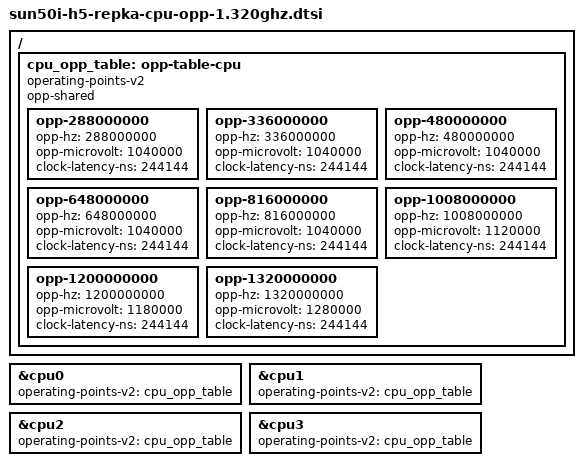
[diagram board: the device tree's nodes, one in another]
// SPDX-License-Identifier: (GPL-2.0+ OR MIT)
// Copyright (C) 2020 Chen-Yu Tsai <wens@csie.org>

/ {
	cpu_opp_table: opp-table-cpu {
		compatible = "operating-points-v2";
		opp-shared;

		opp-288000000 {
			opp-hz = /bits/ 64 <288000000>;
			opp-microvolt = <1040000>;
			clock-latency-ns = <244144>; /* 8 32k periods */
		};

		opp-336000000 {
			opp-hz = /bits/ 64 <336000000>;
			opp-microvolt = <1040000>;
			clock-latency-ns = <244144>; /* 8 32k periods */
		};

		opp-480000000 {
			opp-hz = /bits/ 64 <480000000>;
			opp-microvolt = <1040000>;
			clock-latency-ns = <244144>; /* 8 32k periods */
		};

		opp-648000000 {
			opp-hz = /bits/ 64 <648000000>;
			opp-microvolt = <1040000>;
			clock-latency-ns = <244144>; /* 8 32k periods */
		};

		opp-816000000 {
			opp-hz = /bits/ 64 <816000000>;
			opp-microvolt = <1040000>;
			clock-latency-ns = <244144>; /* 8 32k periods */
		};

		opp-1008000000 {
			opp-hz = /bits/ 64 <1008000000>;
			opp-microvolt = <1120000>;
			clock-latency-ns = <244144>; /* 8 32k periods */
		}; 

		opp-1200000000 {
			opp-hz = /bits/ 64 <1200000000>;
			opp-microvolt = <1180000>;
			clock-latency-ns = <244144>; /* 8 32k periods */
		};

		opp-1320000000 {
			opp-hz = /bits/ 64 <1320000000>;
			opp-microvolt = <1280000>;
			clock-latency-ns = <244144>; /* 8 32k periods  */
		};
	};
};

&cpu0 {
	operating-points-v2 = <&cpu_opp_table>;
};

&cpu1 {
	operating-points-v2 = <&cpu_opp_table>;
};

&cpu2 {
	operating-points-v2 = <&cpu_opp_table>;
};

&cpu3 {
	operating-points-v2 = <&cpu_opp_table>;
};
